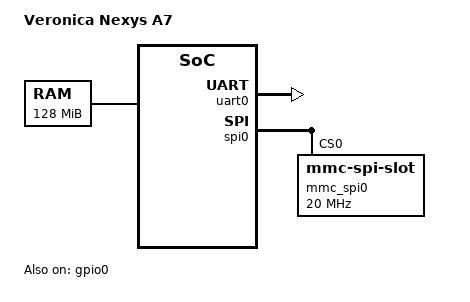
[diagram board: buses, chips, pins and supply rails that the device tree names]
// SPDX-License-Identifier: (GPL-2.0 OR MIT)

#include "veronica.dtsi"
#include <dt-bindings/gpio/gpio.h>

/ {
	model = "Veronica Nexys A7";
	compatible = "Veronica, RV32IMAC";
	
  aliases {
		serial0 = &uart0;
	};

	chosen {
		stdout-path = "serial0";
	};

	memory@80000000 {
    status = "okay";
		device_type = "memory";
		reg = <0x0 0x80000000 0x0 0x8000000>;
	};
};

&soc {
  uart0: serial@44a10000 {
    status = "okay";
    compatible = "xlnx,xps-uartlite-1.00.a";
    reg = <0x0 0x44a10000 0x0 0x10000>;
    interrupt-parent = <&plic0>;
    interrupts = <0 4 4>;
    clock = <50000000>;
  };
  
  gpio0: gpio@44a00000 {
    status = "okay";
    #gpio-cells = <2>;
    compatible = "xlnx,xps-gpio-1.00.a";
    gpio-controller ;
    interrupt-parent = <&plic0>;
    interrupts = <0 6 4>;
    reg = <0x0 0x44a00000 0x0 0x10000 >;
    xlnx,all-inputs = <0x0>;
    xlnx,dout-default = <0x0>;
    xlnx,gpio-width = <0x2>;
    xlnx,interrupt-present = <0x1>;
    xlnx,is-dual = <0x0>;
    xlnx,tri-default = <0xffffffff>;
  };

  spi0: spi@44a20000 {
    status = "okay";
    compatible = "altr,spi-1.0";
    reg = <0x0 0x44a20000 0x0 0x00010000>;
    interrupt-parent = <&plic0>;
    interrupts = <0 5 4>;
    #address-cells = <0x1>;
    #size-cells = <0x0>;

    mmc_spi0: mmc-slot@0 {
      compatible = "mmc-spi-slot";
      reg = <0>;
      status = "okay";
      voltage-ranges = <1800 3600>;
      spi-max-frequency = <20000000>;
      disable-wp;
      disable-cd;
    };
  };
};
